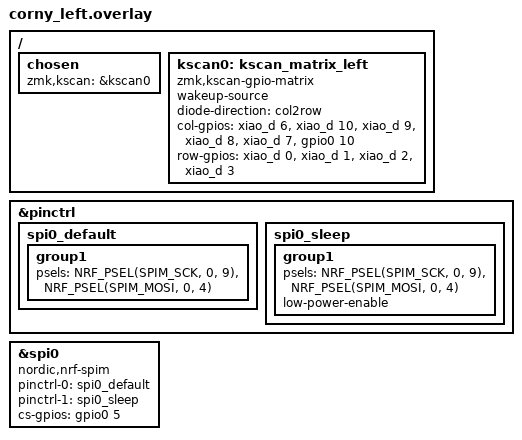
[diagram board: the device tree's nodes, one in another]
#include "corny.dtsi"

/* nice!view SPI bus - custom pins to avoid conflict with matrix rows */
&pinctrl {
    spi0_default: spi0_default {
        group1 {
            psels = <NRF_PSEL(SPIM_SCK, 0, 9)>,    /* P0.09 (NFC) */
                    <NRF_PSEL(SPIM_MOSI, 0, 4)>;   /* D4 / P0.04 */
        };
    };
    spi0_sleep: spi0_sleep {
        group1 {
            psels = <NRF_PSEL(SPIM_SCK, 0, 9)>,
                    <NRF_PSEL(SPIM_MOSI, 0, 4)>;
            low-power-enable;
        };
    };
};

nice_view_spi: &spi0 {
    compatible = "nordic,nrf-spim";
    pinctrl-0 = <&spi0_default>;
    pinctrl-1 = <&spi0_sleep>;
    pinctrl-names = "default", "sleep";
    cs-gpios = <&gpio0 5 GPIO_ACTIVE_HIGH>;   /* D5 / P0.05 */
};

/ {
    chosen {
        zmk,kscan = &kscan0;
    };

    kscan0: kscan_matrix_left {
        compatible = "zmk,kscan-gpio-matrix";
        wakeup-source;
        diode-direction = "col2row";

    col-gpios
        = <&xiao_d 6 GPIO_ACTIVE_HIGH>
        , <&xiao_d 10 GPIO_ACTIVE_HIGH>
        , <&xiao_d 9 GPIO_ACTIVE_HIGH>
        , <&xiao_d 8 GPIO_ACTIVE_HIGH>
        , <&xiao_d 7 GPIO_ACTIVE_HIGH>
        , <&gpio0 10 GPIO_ACTIVE_HIGH>
        ;

    row-gpios
      = <&xiao_d 0 (GPIO_ACTIVE_HIGH | GPIO_PULL_DOWN)>
      , <&xiao_d 1 (GPIO_ACTIVE_HIGH | GPIO_PULL_DOWN)>
      , <&xiao_d 2 (GPIO_ACTIVE_HIGH | GPIO_PULL_DOWN)>
      , <&xiao_d 3 (GPIO_ACTIVE_HIGH | GPIO_PULL_DOWN)>
      ;

    };
};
